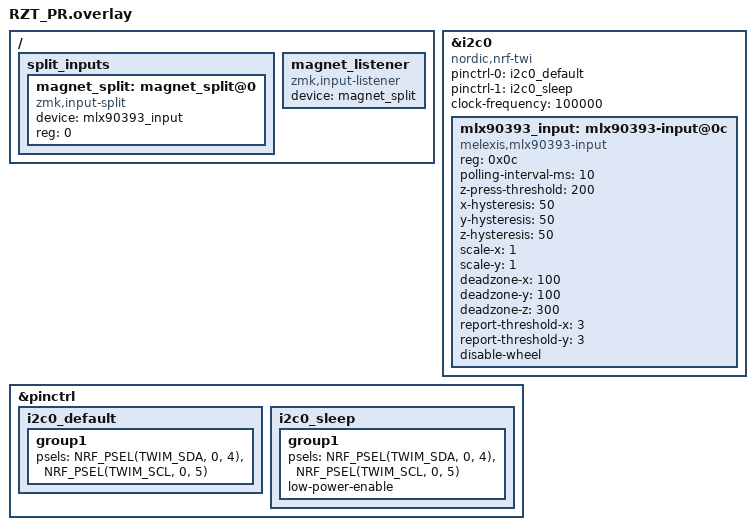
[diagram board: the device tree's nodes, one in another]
#include <dt-bindings/zmk/keys.h>
#include <dt-bindings/zmk/pointing.h>

&i2c0 {
    status = "okay";
    compatible = "nordic,nrf-twi";
    pinctrl-0 = <&i2c0_default>;
    pinctrl-1 = <&i2c0_sleep>;
    pinctrl-names = "default", "sleep";
    clock-frequency = <100000>; 
    
    mlx90393_input: mlx90393-input@0c {
        compatible = "melexis,mlx90393-input";
        reg = <0x0c>;
        
        polling-interval-ms = <10>;
        z-press-threshold = <200>;
        x-hysteresis = <50>;
        y-hysteresis = <50>;
        z-hysteresis = <50>;
        
        scale-x = <1>;
        scale-y = <1>;

        deadzone-x = <100>;
        deadzone-y = <100>;
        deadzone-z = <300>;
        report-threshold-x = <3>;
        report-threshold-y = <3>;
        disable-wheel;
    };
};

&pinctrl {    
    i2c0_default: i2c0_default {
        group1 {
            psels = <NRF_PSEL(TWIM_SDA, 0,  4)>,
                    <NRF_PSEL(TWIM_SCL, 0,  5)>;
            // bias-pull-up;
        };
    };
      
    i2c0_sleep: i2c0_sleep {
        group1 {
            psels = <NRF_PSEL(TWIM_SDA, 0,  4)>,
                    <NRF_PSEL(TWIM_SCL, 0,  5)>;
            low-power-enable;
            // bias-pull-up;
        };
    };
};

/*input-split*/
/ {
    split_inputs {
        #address-cells = <1>;
        #size-cells = <0>;

        magnet_split: magnet_split@0 {
            compatible = "zmk,input-split";
            status = "okay";
            device = <&mlx90393_input>;
            reg = <0>;
        };
    };

    magnet_listener: magnet_listener {
        compatible = "zmk,input-listener";
        status = "okay";
        device = <&magnet_split>;
    };
};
